AUTOSAR XML (schema 00044)
package /E40_Platform_System_SystemPackage/Components
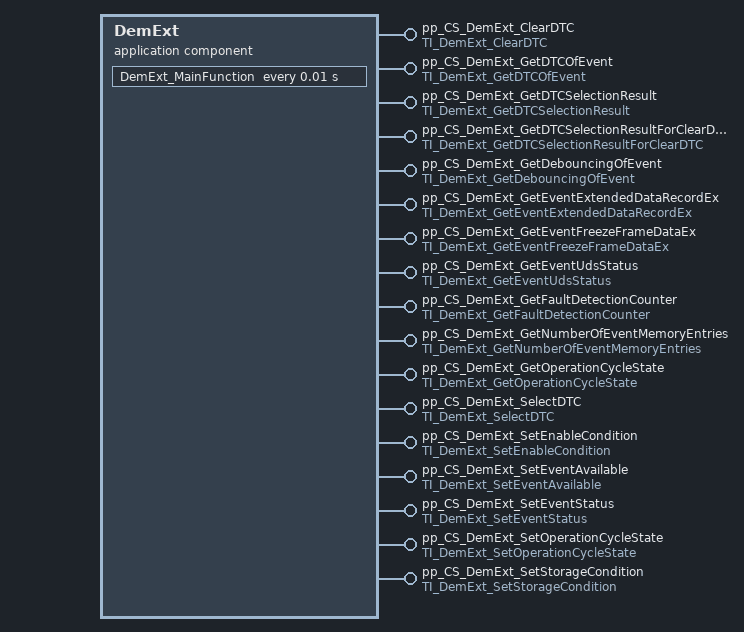
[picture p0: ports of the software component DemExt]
  application sw component type DemExt
    17 x provide port:
      pp_CS_DemExt_ClearDTC: server-com-spec{operation=DemExt_ClearDTC, queue-length=1}, provided-interface=TI_DemExt_ClearDTC
      pp_CS_DemExt_GetDTCOfEvent: server-com-spec{operation=DemExt_GetDTCOfEvent, queue-length=1}, provided-interface=TI_DemExt_GetDTCOfEvent
      pp_CS_DemExt_GetDTCSelectionResult: server-com-spec{operation=DemExt_GetDTCSelectionResult, queue-length=1}, provided-interface=TI_DemExt_GetDTCSelectionResult
      pp_CS_DemExt_GetDTCSelectionResultForClearDTC: server-com-spec{operation=DemExt_GetDTCSelectionResultForClearDTC, queue-length=1}, provided-interface=TI_DemExt_GetDTCSelectionResultForClearDTC
      pp_CS_DemExt_GetDebouncingOfEvent: server-com-spec{operation=DemExt_GetDebouncingOfEvent, queue-length=1}, provided-interface=TI_DemExt_GetDebouncingOfEvent
      pp_CS_DemExt_GetEventExtendedDataRecordEx: server-com-spec{operation=DemExt_GetEventExtendedDataRecordEx, queue-length=1}, provided-interface=TI_DemExt_GetEventExtendedDataRecordEx
      pp_CS_DemExt_GetEventFreezeFrameDataEx: server-com-spec{operation=DemExt_GetEventFreezeFrameDataEx, queue-length=1}, provided-interface=TI_DemExt_GetEventFreezeFrameDataEx
      pp_CS_DemExt_GetEventUdsStatus: server-com-spec{operation=DemExt_GetEventUdsStatus, queue-length=1}, provided-interface=TI_DemExt_GetEventUdsStatus
      pp_CS_DemExt_GetFaultDetectionCounter: server-com-spec{operation=DemExt_GetFaultDetectionCounter, queue-length=1}, provided-interface=TI_DemExt_GetFaultDetectionCounter
      pp_CS_DemExt_GetNumberOfEventMemoryEntries: server-com-spec{operation=DemExt_GetNumberOfEventMemoryEntries, queue-length=1}, provided-interface=TI_DemExt_GetNumberOfEventMemoryEntries
      pp_CS_DemExt_GetOperationCycleState: server-com-spec{operation=DemExt_GetOperationCycleState, queue-length=1}, provided-interface=TI_DemExt_GetOperationCycleState
      pp_CS_DemExt_SelectDTC: server-com-spec{operation=DemExt_SelectDTC, queue-length=1}, provided-interface=TI_DemExt_SelectDTC
      pp_CS_DemExt_SetEnableCondition: server-com-spec{operation=DemExt_SetEnableCondition, queue-length=1}, provided-interface=TI_DemExt_SetEnableCondition
      pp_CS_DemExt_SetEventAvailable: server-com-spec{operation=DemExt_SetEventAvailable, queue-length=1}, provided-interface=TI_DemExt_SetEventAvailable
      pp_CS_DemExt_SetEventStatus: server-com-spec{operation=DemExt_SetEventStatus, queue-length=1}, provided-interface=TI_DemExt_SetEventStatus
      pp_CS_DemExt_SetOperationCycleState: server-com-spec{operation=DemExt_SetOperationCycleState, queue-length=1}, provided-interface=TI_DemExt_SetOperationCycleState
      pp_CS_DemExt_SetStorageCondition: server-com-spec{operation=DemExt_SetStorageCondition, queue-length=1}, provided-interface=TI_DemExt_SetStorageCondition
    behavior IB_DemExt
      16 x operation invoked event:
        OIE_pp_CS_DemExt_ClearDTC_DemExt_ClearDTCTrigByDemExt_ClearDTC: start-on-event=DemExt_ClearDTC, operation=pp_CS_DemExt_ClearDTC.DemExt_ClearDTC
        OIE_pp_CS_DemExt_GetDTCOfEvent_DemExt_GetDTCOfEventTrigByDemExt_GetDTCOfEvent: start-on-event=DemExt_GetDTCOfEvent, operation=pp_CS_DemExt_GetDTCOfEvent.DemExt_GetDTCOfEvent
        OIE_pp_CS_DemExt_GetDTCSelectionResult_DemExt_GetDTCSelectionResultTrigByDemExt_GetDTCSelectionResult: start-on-event=DemExt_GetDTCSelectionResult, operation=pp_CS_DemExt_GetDTCSelectionResult.DemExt_GetDTCSelectionResult
        OIE_pp_CS_DemExt_GetDebouncingOfEvent_DemExt_GetDebouncingOfEventTrigByDemExt_GetDebouncingOfEvent: start-on-event=DemExt_GetDebouncingOfEvent, operation=pp_CS_DemExt_GetDebouncingOfEvent.DemExt_GetDebouncingOfEvent
        OIE_pp_CS_DemExt_GetEventExtendedDataRecordEx_DemExt_GetEventExtendedDataRecordExTrigByDemExt_GetEventExtendedDataRecordEx: start-on-event=DemExt_GetEventExtendedDataRecordEx, operation=pp_CS_DemExt_GetEventExtendedDataRecordEx.DemExt_GetEventExtendedDataRecordEx
        OIE_pp_CS_DemExt_GetEventFreezeFrameDataEx_DemExt_GetEventFreezeFrameDataExTrigByDemExt_GetEventFreezeFrameDataEx: start-on-event=DemExt_GetEventFreezeFrameDataEx, operation=pp_CS_DemExt_GetEventFreezeFrameDataEx.DemExt_GetEventFreezeFrameDataEx
        OIE_pp_CS_DemExt_GetEventUdsStatus_DemExt_GetEventUdsStatusTrigByDemExt_GetEventUdsStatus: start-on-event=DemExt_GetEventUdsStatus, operation=pp_CS_DemExt_GetEventUdsStatus.DemExt_GetEventUdsStatus
        OIE_pp_CS_DemExt_GetFaultDetectionCounter_DemExt_GetFaultDetectionCounterTrigByDemExt_GetFaultDetectionCounter: start-on-event=DemExt_GetFaultDetectionCounter, operation=pp_CS_DemExt_GetFaultDetectionCounter.DemExt_GetFaultDetectionCounter
        OIE_pp_CS_DemExt_GetNumberOfEventMemoryEntries_DemExt_GetNumberOfEventMemoryEntriesTrigByDemExt_GetNumberOfEventMemoryEntries: start-on-event=DemExt_GetNumberOfEventMemoryEntries, operation=pp_CS_DemExt_GetNumberOfEventMemoryEntries.DemExt_GetNumberOfEventMemoryEntries
        OIE_pp_CS_DemExt_GetOperationCycleState_DemExt_GetOperationCycleStateTrigByDemExt_GetOperationCycleState: start-on-event=DemExt_GetOperationCycleState, operation=pp_CS_DemExt_GetOperationCycleState.DemExt_GetOperationCycleState
        OIE_pp_CS_DemExt_SelectDTC_DemExt_SelectDTCTrigByDemExt_SelectDTC: start-on-event=DemExt_SelectDTC, operation=pp_CS_DemExt_SelectDTC.DemExt_SelectDTC
        OIE_pp_CS_DemExt_SetEnableCondition_DemExt_SetEnableConditionTrigByDemExt_SetEnableCondition: start-on-event=DemExt_SetEnableCondition, operation=pp_CS_DemExt_SetEnableCondition.DemExt_SetEnableCondition
        OIE_pp_CS_DemExt_SetEventAvailable_DemExt_SetEventAvailableTrigByDemExt_SetEventAvailable: start-on-event=DemExt_SetEventAvailable, operation=pp_CS_DemExt_SetEventAvailable.DemExt_SetEventAvailable
        OIE_pp_CS_DemExt_SetEventStatus_DemExt_SetEventStatusTrigByDemExt_SetEventStatus: start-on-event=DemExt_SetEventStatus, operation=pp_CS_DemExt_SetEventStatus.DemExt_SetEventStatus
        OIE_pp_CS_DemExt_SetOperationCycleState_DemExt_SetOperationCycleStateTrigByDemExt_SetOperationCycleState: start-on-event=DemExt_SetOperationCycleState, operation=pp_CS_DemExt_SetOperationCycleState.DemExt_SetOperationCycleState
        OIE_pp_CS_DemExt_SetStorageCondition_DemExt_SetStorageConditionTrigByDemExt_SetStorageCondition: start-on-event=DemExt_SetStorageCondition, operation=pp_CS_DemExt_SetStorageCondition.DemExt_SetStorageCondition
      timing event TEDemExt_MainFunction: start-on-event=DemExt_MainFunction, period=0.01
      operation invoked event OperationInvokeEvent_111: start-on-event=DemExt_GetDTCSelectionResultForClearDTC, operation=pp_CS_DemExt_GetDTCSelectionResultForClearDTC.DemExt_GetDTCSelectionResultForClearDTC
      port-api-options:
        enable-take-address=false, indirect-api=false, port=pp_CS_DemExt_ClearDTC
        enable-take-address=false, indirect-api=false, port=pp_CS_DemExt_GetDTCOfEvent
        enable-take-address=false, indirect-api=false, port=pp_CS_DemExt_GetDTCSelectionResult
        enable-take-address=false, indirect-api=false, port=pp_CS_DemExt_GetDTCSelectionResultForClearDTC
        enable-take-address=false, indirect-api=false, port=pp_CS_DemExt_GetDebouncingOfEvent
        enable-take-address=false, indirect-api=false, port=pp_CS_DemExt_GetEventExtendedDataRecordEx
        enable-take-address=false, indirect-api=false, port=pp_CS_DemExt_GetEventFreezeFrameDataEx
        enable-take-address=false, indirect-api=false, port=pp_CS_DemExt_GetEventUdsStatus
        enable-take-address=false, indirect-api=false, port=pp_CS_DemExt_GetFaultDetectionCounter
        enable-take-address=false, indirect-api=false, port=pp_CS_DemExt_GetNumberOfEventMemoryEntries
        enable-take-address=false, indirect-api=false, port=pp_CS_DemExt_GetOperationCycleState
        enable-take-address=false, indirect-api=false, port=pp_CS_DemExt_SelectDTC
        enable-take-address=false, indirect-api=false, port=pp_CS_DemExt_SetEnableCondition
        enable-take-address=false, indirect-api=false, port=pp_CS_DemExt_SetEventAvailable
        enable-take-address=false, indirect-api=false, port=pp_CS_DemExt_SetEventStatus
        enable-take-address=false, indirect-api=false, port=pp_CS_DemExt_SetOperationCycleState
        enable-take-address=false, indirect-api=false, port=pp_CS_DemExt_SetStorageCondition
      18 x runnable, all with can-be-invoked-concurrently=true:
        DemExt_ClearDTC
        DemExt_GetDTCOfEvent
        DemExt_GetDTCSelectionResult
        DemExt_GetDTCSelectionResultForClearDTC
        DemExt_GetDebouncingOfEvent
        DemExt_GetEventExtendedDataRecordEx
        DemExt_GetEventFreezeFrameDataEx
        DemExt_GetEventUdsStatus
        DemExt_GetFaultDetectionCounter
        DemExt_GetNumberOfEventMemoryEntries
        DemExt_GetOperationCycleState
        DemExt_SelectDTC
        DemExt_SetEnableCondition
        DemExt_SetEventAvailable
        DemExt_SetEventStatus
        DemExt_SetOperationCycleState
        DemExt_SetStorageCondition
        DemExt_MainFunction
  swc implementation IMPL_DemExt: behavior=IB_DemExt
